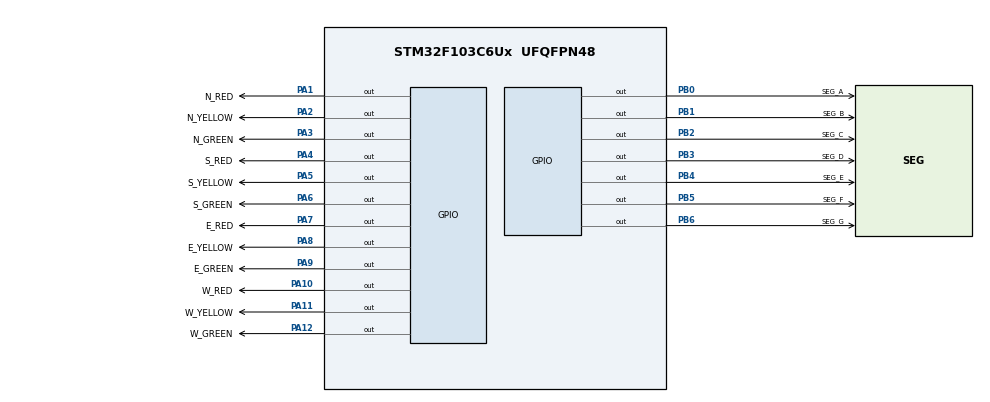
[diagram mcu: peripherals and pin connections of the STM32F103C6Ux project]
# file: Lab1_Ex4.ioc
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Mcu.Family=STM32F1
Mcu.Name=STM32F103C6Ux
Mcu.Package=UFQFPN48
NVIC.PriorityGroup=NVIC_PRIORITYGROUP_4
PA1.GPIO_Label=N_RED
PA1.PinState=GPIO_PIN_SET
PA1.Signal=GPIO_Output
PA10.GPIO_Label=W_RED
PA10.PinState=GPIO_PIN_SET
PA10.Signal=GPIO_Output
PA11.GPIO_Label=W_YELLOW
PA11.PinState=GPIO_PIN_SET
PA11.Signal=GPIO_Output
PA12.GPIO_Label=W_GREEN
PA12.PinState=GPIO_PIN_SET
PA12.Signal=GPIO_Output
PA13.Mode=Serial_Wire
PA13.Signal=SYS_JTMS-SWDIO
PA14.Mode=Serial_Wire
PA14.Signal=SYS_JTCK-SWCLK
PA2.GPIO_Label=N_YELLOW
PA2.PinState=GPIO_PIN_SET
PA2.Signal=GPIO_Output
PA3.GPIO_Label=N_GREEN
PA3.PinState=GPIO_PIN_SET
PA3.Signal=GPIO_Output
PA4.GPIO_Label=S_RED
PA4.PinState=GPIO_PIN_SET
PA4.Signal=GPIO_Output
PA5.GPIO_Label=S_YELLOW
PA5.PinState=GPIO_PIN_SET
PA5.Signal=GPIO_Output
PA6.GPIO_Label=S_GREEN
PA6.PinState=GPIO_PIN_SET
PA6.Signal=GPIO_Output
PA7.GPIO_Label=E_RED
PA7.PinState=GPIO_PIN_SET
PA7.Signal=GPIO_Output
PA8.GPIO_Label=E_YELLOW
PA8.PinState=GPIO_PIN_SET
PA8.Signal=GPIO_Output
PA9.GPIO_Label=E_GREEN
PA9.PinState=GPIO_PIN_SET
PA9.Signal=GPIO_Output
PB0.GPIO_Label=SEG_A
PB0.PinState=GPIO_PIN_SET
PB0.Signal=GPIO_Output
PB1.GPIO_Label=SEG_B
PB1.PinState=GPIO_PIN_SET
PB1.Signal=GPIO_Output
PB2.GPIO_Label=SEG_C
PB2.PinState=GPIO_PIN_SET
PB2.Signal=GPIO_Output
PB3.GPIO_Label=SEG_D
PB3.PinState=GPIO_PIN_SET
PB3.Signal=GPIO_Output
PB4.GPIO_Label=SEG_E
PB4.PinState=GPIO_PIN_SET
PB4.Signal=GPIO_Output
PB5.GPIO_Label=SEG_F
PB5.PinState=GPIO_PIN_SET
PB5.Signal=GPIO_Output
PB6.GPIO_Label=SEG_G
PB6.PinState=GPIO_PIN_SET
PB6.Signal=GPIO_Output
ProjectManager.HeapSize=0x200
ProjectManager.StackSize=0x400
ProjectManager.TargetToolchain=STM32CubeIDE
RCC.APB1Freq_Value=8000000
RCC.APB2Freq_Value=8000000
board=custom

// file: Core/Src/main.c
/* USER CODE BEGIN Header */
/**
  ******************************************************************************
  * @file           : main.c
  * @brief          : Main program body
  *                   Lab 1 - Exercise 4 - LED 7 doan chung anode, ham display7SEG()
  ******************************************************************************
  * @attention
  *
  * <h2><center>&copy; Copyright (c) 2026 STMicroelectronics.
  * All rights reserved.</center></h2>
  *
  * This software component is licensed by ST under BSD 3-Clause license,
  * the "License"; You may not use this file except in compliance with the
  * License. You may obtain a copy of the License at:
  *                        opensource.org/licenses/BSD-3-Clause
  *
  ******************************************************************************
  */
/* USER CODE END Header */
#include "main.h"

/* USER CODE BEGIN Includes */
#include "seven_seg.h"
/* USER CODE END Includes */

/* USER CODE BEGIN PV */
int counter = 0;
/* USER CODE END PV */

void SystemClock_Config(void);
static void MX_GPIO_Init(void);

int main(void)
{

  /* MCU Configuration--------------------------------------------------------*/

  /* Reset of all peripherals, Initializes the Flash interface and the Systick. */
  HAL_Init();

  /* Configure the system clock */
  SystemClock_Config();

  /* Initialize all configured peripherals */
  MX_GPIO_Init();

  /* Infinite loop */
  /* USER CODE BEGIN WHILE */
  while (1)
  {
    /* Doan code test theo de bai: dem 0 -> 9 moi giay */
    if (counter >= 10) counter = 0;
    display7SEG(counter++);
    HAL_Delay(1000);
    /* USER CODE END WHILE */

  }
}

void SystemClock_Config(void)
{
  RCC_OscInitTypeDef RCC_OscInitStruct = {0};
  RCC_ClkInitTypeDef RCC_ClkInitStruct = {0};

  /** Initializes the RCC Oscillators according to the specified parameters
  * in the RCC_OscInitTypeDef structure.
  */
  RCC_OscInitStruct.OscillatorType = RCC_OSCILLATORTYPE_HSI;
  RCC_OscInitStruct.HSIState = RCC_HSI_ON;
  RCC_OscInitStruct.HSICalibrationValue = RCC_HSICALIBRATION_DEFAULT;
  RCC_OscInitStruct.PLL.PLLState = RCC_PLL_NONE;
  if (HAL_RCC_OscConfig(&RCC_OscInitStruct) != HAL_OK)
  {
    Error_Handler();
  }
  /** Initializes the CPU, AHB and APB buses clocks
  */
  RCC_ClkInitStruct.ClockType = RCC_CLOCKTYPE_HCLK|RCC_CLOCKTYPE_SYSCLK
                              |RCC_CLOCKTYPE_PCLK1|RCC_CLOCKTYPE_PCLK2;
  RCC_ClkInitStruct.SYSCLKSource = RCC_SYSCLKSOURCE_HSI;
  RCC_ClkInitStruct.AHBCLKDivider = RCC_SYSCLK_DIV1;
  RCC_ClkInitStruct.APB1CLKDivider = RCC_HCLK_DIV1;
  RCC_ClkInitStruct.APB2CLKDivider = RCC_HCLK_DIV1;

  if (HAL_RCC_ClockConfig(&RCC_ClkInitStruct, FLASH_LATENCY_0) != HAL_OK)
  {
    Error_Handler();
  }
}

static void MX_GPIO_Init(void)
{
  GPIO_InitTypeDef GPIO_InitStruct = {0};

  /* GPIO Ports Clock Enable */
  __HAL_RCC_GPIOA_CLK_ENABLE();
  __HAL_RCC_GPIOB_CLK_ENABLE();

  /*Configure GPIO pin Output Level */
  HAL_GPIO_WritePin(GPIOA, N_RED_Pin|N_YELLOW_Pin|N_GREEN_Pin
                          |S_RED_Pin|S_YELLOW_Pin|S_GREEN_Pin
                          |E_RED_Pin|E_YELLOW_Pin|E_GREEN_Pin
                          |W_RED_Pin|W_YELLOW_Pin|W_GREEN_Pin, GPIO_PIN_SET);

  /*Configure GPIO pin Output Level */
  HAL_GPIO_WritePin(GPIOB, SEG_A_Pin|SEG_B_Pin|SEG_C_Pin
                          |SEG_D_Pin|SEG_E_Pin|SEG_F_Pin
                          |SEG_G_Pin, GPIO_PIN_SET);

  /*Configure GPIO pins : N_RED_Pin N_YELLOW_Pin N_GREEN_Pin S_RED_Pin S_YELLOW_Pin S_GREEN_Pin E_RED_Pin E_YELLOW_Pin E_GREEN_Pin W_RED_Pin W_YELLOW_Pin W_GREEN_Pin */
  GPIO_InitStruct.Pin = N_RED_Pin|N_YELLOW_Pin|N_GREEN_Pin
                          |S_RED_Pin|S_YELLOW_Pin|S_GREEN_Pin
                          |E_RED_Pin|E_YELLOW_Pin|E_GREEN_Pin
                          |W_RED_Pin|W_YELLOW_Pin|W_GREEN_Pin;
  GPIO_InitStruct.Mode = GPIO_MODE_OUTPUT_PP;
  GPIO_InitStruct.Pull = GPIO_NOPULL;
  GPIO_InitStruct.Speed = GPIO_SPEED_FREQ_LOW;
  HAL_GPIO_Init(GPIOA, &GPIO_InitStruct);

  /*Configure GPIO pins : SEG_A_Pin SEG_B_Pin SEG_C_Pin SEG_D_Pin SEG_E_Pin SEG_F_Pin SEG_G_Pin */
  GPIO_InitStruct.Pin = SEG_A_Pin|SEG_B_Pin|SEG_C_Pin
                          |SEG_D_Pin|SEG_E_Pin|SEG_F_Pin
                          |SEG_G_Pin;
  GPIO_InitStruct.Mode = GPIO_MODE_OUTPUT_PP;
  GPIO_InitStruct.Pull = GPIO_NOPULL;
  GPIO_InitStruct.Speed = GPIO_SPEED_FREQ_LOW;
  HAL_GPIO_Init(GPIOB, &GPIO_InitStruct);

}

void Error_Handler(void)
{
  __disable_irq();
  while (1)
  {
  }
}

/************************ (C) COPYRIGHT STMicroelectronics *****END OF FILE****/
